# AVR128DA32S register map
Vendor: Atmel; File version: 1.0
CPU: other r0p0, little endian, no MPU, no FPU, 4 interrupt priority bits
Registers are 8-bit, read-write, reset 0x0 unless marked. A register's access mark holds for its fields unless they carry their own. Offsets are from the block's base; [hi:lo] are bit positions; {n}, {i} and the like mark numbered series.

## RSTCTRL — Reset controller
Base 0x00800040
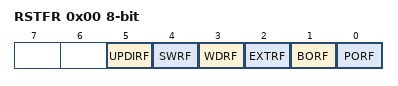
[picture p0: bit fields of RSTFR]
0x00 RSTFR — Reset Flags
  [5] UPDIRF — UPDI Reset flag
  [4] SWRF — Software Reset flag
  [3] WDRF — Watch dog Reset flag
  [2] EXTRF — External Reset flag
  [1] BORF — Brown out detector Reset flag
  [0] PORF — Power on Reset flag
0x01 SWRR — Software Reset
  [0] SWRST — Software reset enable

## RTC — Real-Time Counter
Base 0x00800140
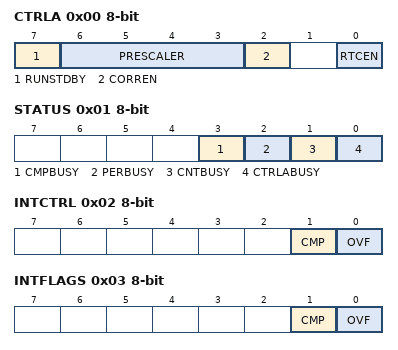
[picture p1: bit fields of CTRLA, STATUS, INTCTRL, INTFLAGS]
0x00 CTRLA — Control A
  [7] RUNSTDBY — Run In Standby
  [6:3] PRESCALER — Prescaling Factor
    0=DIV1 (RTC Clock / 1); 1=DIV2 (RTC Clock / 2); 2=DIV4 (RTC Clock / 4); 3=DIV8 (RTC Clock / 8); 4=DIV16 (RTC Clock / 16); 5=DIV32 (RTC Clock / 32); 6=DIV64 (RTC Clock / 64); 7=DIV128 (RTC Clock / 128); 8=DIV256 (RTC Clock / 256); 9=DIV512 (RTC Clock / 512); 10=DIV1024 (RTC Clock / 1024); 11=DIV2048 (RTC Clock / 2048); 12=DIV4096 (RTC Clock / 4096); 13=DIV8192 (RTC Clock / 8192); 14=DIV16384 (RTC Clock / 16384); 15=DIV32768 (RTC Clock / 32768)
  [2] CORREN — Correction enable
  [0] RTCEN — Enable
0x01 STATUS ro
  [3] CMPBUSY — Comparator Synchronization Busy Flag
  [2] PERBUSY — Period Synchronization Busy Flag
  [1] CNTBUSY — Count Synchronization Busy Flag
  [0] CTRLABUSY — CTRLA Synchronization Busy Flag
0x02 INTCTRL — Interrupt Control
  [1] CMP — Compare Match Interrupt enable
  [0] OVF — Overflow Interrupt enable
0x03 INTFLAGS — Interrupt Flags
  [1] CMP — Compare Match Interrupt
  [0] OVF — Overflow Interrupt Flag
0x04 TEMP — Temporary
0x05 DBGCTRL — Debug control
  [0] DBGRUN — Run in debug
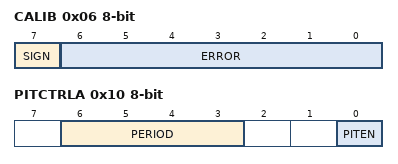
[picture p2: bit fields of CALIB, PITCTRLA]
0x06 CALIB — Calibration
  [7] SIGN — Error Correction Sign Bit
  [6:0] ERROR — Error Correction Value
0x07 CLKSEL — Clock Select
  [1:0] CLKSEL
    0=OSC32K (32.768 kHz from OSC32K); 1=OSC1K (1.024 kHz from OSC32K); 2=XOSC32K (32.768 kHz from XOSC32K); 3=EXTCLK (External Clock)
0x08 CNT 16-bit (reset mask 0xFF) — Counter
0x0A PER 16-bit (reset mask 0xFF) — Period
0x0C CMP 16-bit (reset mask 0xFF) — Compare
0x10 PITCTRLA — PIT Control A
  [6:3] PERIOD
    0=OFF; 1=CYC4 (RTC Clock Cycles 4); 2=CYC8 (RTC Clock Cycles 8); 3=CYC16 (RTC Clock Cycles 16); 4=CYC32 (RTC Clock Cycles 32); 5=CYC64 (RTC Clock Cycles 64); 6=CYC128 (RTC Clock Cycles 128); 7=CYC256 (RTC Clock Cycles 256); 8=CYC512 (RTC Clock Cycles 512); 9=CYC1024 (RTC Clock Cycles 1024); 10=CYC2048 (RTC Clock Cycles 2048); 11=CYC4096 (RTC Clock Cycles 4096); 12=CYC8192 (RTC Clock Cycles 8192); 13=CYC16384 (RTC Clock Cycles 16384); 14=CYC32768 (RTC Clock Cycles 32768)
  [0] PITEN — Enable
0x11 PITSTATUS ro
  [0] CTRLBUSY — CTRLA Synchronization Busy Flag
0x12 PITINTCTRL — PIT Interrupt Control
  [0] PI — Periodic Interrupt
0x13 PITINTFLAGS — PIT Interrupt Flags
  [0] PI — Periodic Interrupt
0x15 PITDBGCTRL — PIT Debug control
  [0] DBGRUN — Run in debug

## SIGROW — Signature row
Base 0x00801100
{0x0+i} DEVICEID{i} ro (i=0..2) — Device ID Byte {i}
0x04 TEMPSENSE0 16-bit ro (reset mask 0xFF) — Temperature Calibration 0
0x06 TEMPSENSE1 16-bit ro (reset mask 0xFF) — Temperature Calibration 1
{0x10+i} SERNUM{i} ro (i=0..5) — LOTNUM{i}
0x16 SERNUM6 ro — RANDOM
0x17 SERNUM7 ro — SCRIBE
0x18 SERNUM8 ro — XPOS0
0x19 SERNUM9 ro — XPOS1
0x1A SERNUM10 ro — YPOS0
0x1B SERNUM11 ro — YPOS1
{0x10+i} SERNUM{i} ro (i=12..15) — RES{i-12}

## SLPCTRL — Sleep Controller
Base 0x00800050
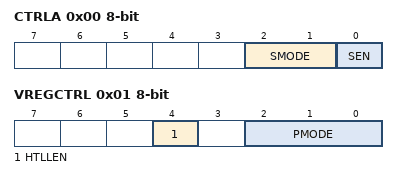
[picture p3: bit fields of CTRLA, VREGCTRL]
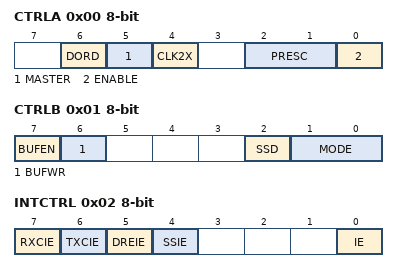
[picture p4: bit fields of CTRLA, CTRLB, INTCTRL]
0x00 CTRLA — Control A
  [2:1] SMODE — Sleep mode
    0=IDLE (Idle mode); 1=STDBY (Standby Mode); 2=PDOWN (Power-down Mode)
  [0] SEN — Sleep enable
0x01 VREGCTRL — Control B
  [4] HTLLEN — High Temperature Low Leakage Enable
    0=OFF (Disabled); 1=ON (Enabled)
  [2:0] PMODE — Performance Mode
    0=AUTO; 1=FULL

## SPI0 — Serial Peripheral Interface
Base 0x00800940
Same registers: SPI1 0x00800960
0x00 CTRLA — Control A
  [6] DORD — Data Order Setting
  [5] MASTER — Host Operation Enable
  [4] CLK2X — Enable Double Speed
  [2:1] PRESC — Prescaler
    0=DIV4 (CLK_PER / 4); 1=DIV16 (CLK_PER / 16); 2=DIV64 (CLK_PER / 64); 3=DIV128 (CLK_PER / 128)
  [0] ENABLE — Enable Module
0x01 CTRLB — Control B
  [7] BUFEN — Buffer Mode Enable
  [6] BUFWR — Buffer Mode Wait for Receive
  [2] SSD — SPI Select Disable
  [1:0] MODE — SPI Mode
    {v}=SPI Mode {v} (v=0..3)
0x02 INTCTRL — Interrupt Control
  [7] RXCIE — Receive Complete Interrupt Enable
  [6] TXCIE — Transfer Complete Interrupt Enable
  [5] DREIE — Data Register Empty Interrupt Enable
  [4] SSIE — SPI Select Trigger Interrupt Enable
  [0] IE — Interrupt Enable
0x03 INTFLAGS — Interrupt Flags
  [7] IF — Interrupt Flag
  [7] RXCIF — Receive Complete Interrupt Flag
  [6] TXCIF — Transfer Complete Interrupt Flag
  [6] WRCOL — Write Collision
  [5] DREIF — Data Register Empty Interrupt Flag
  [4] SSIF — SPI Select Trigger Interrupt Flag
  [0] BUFOVF — Buffer Overflow
0x04 DATA
